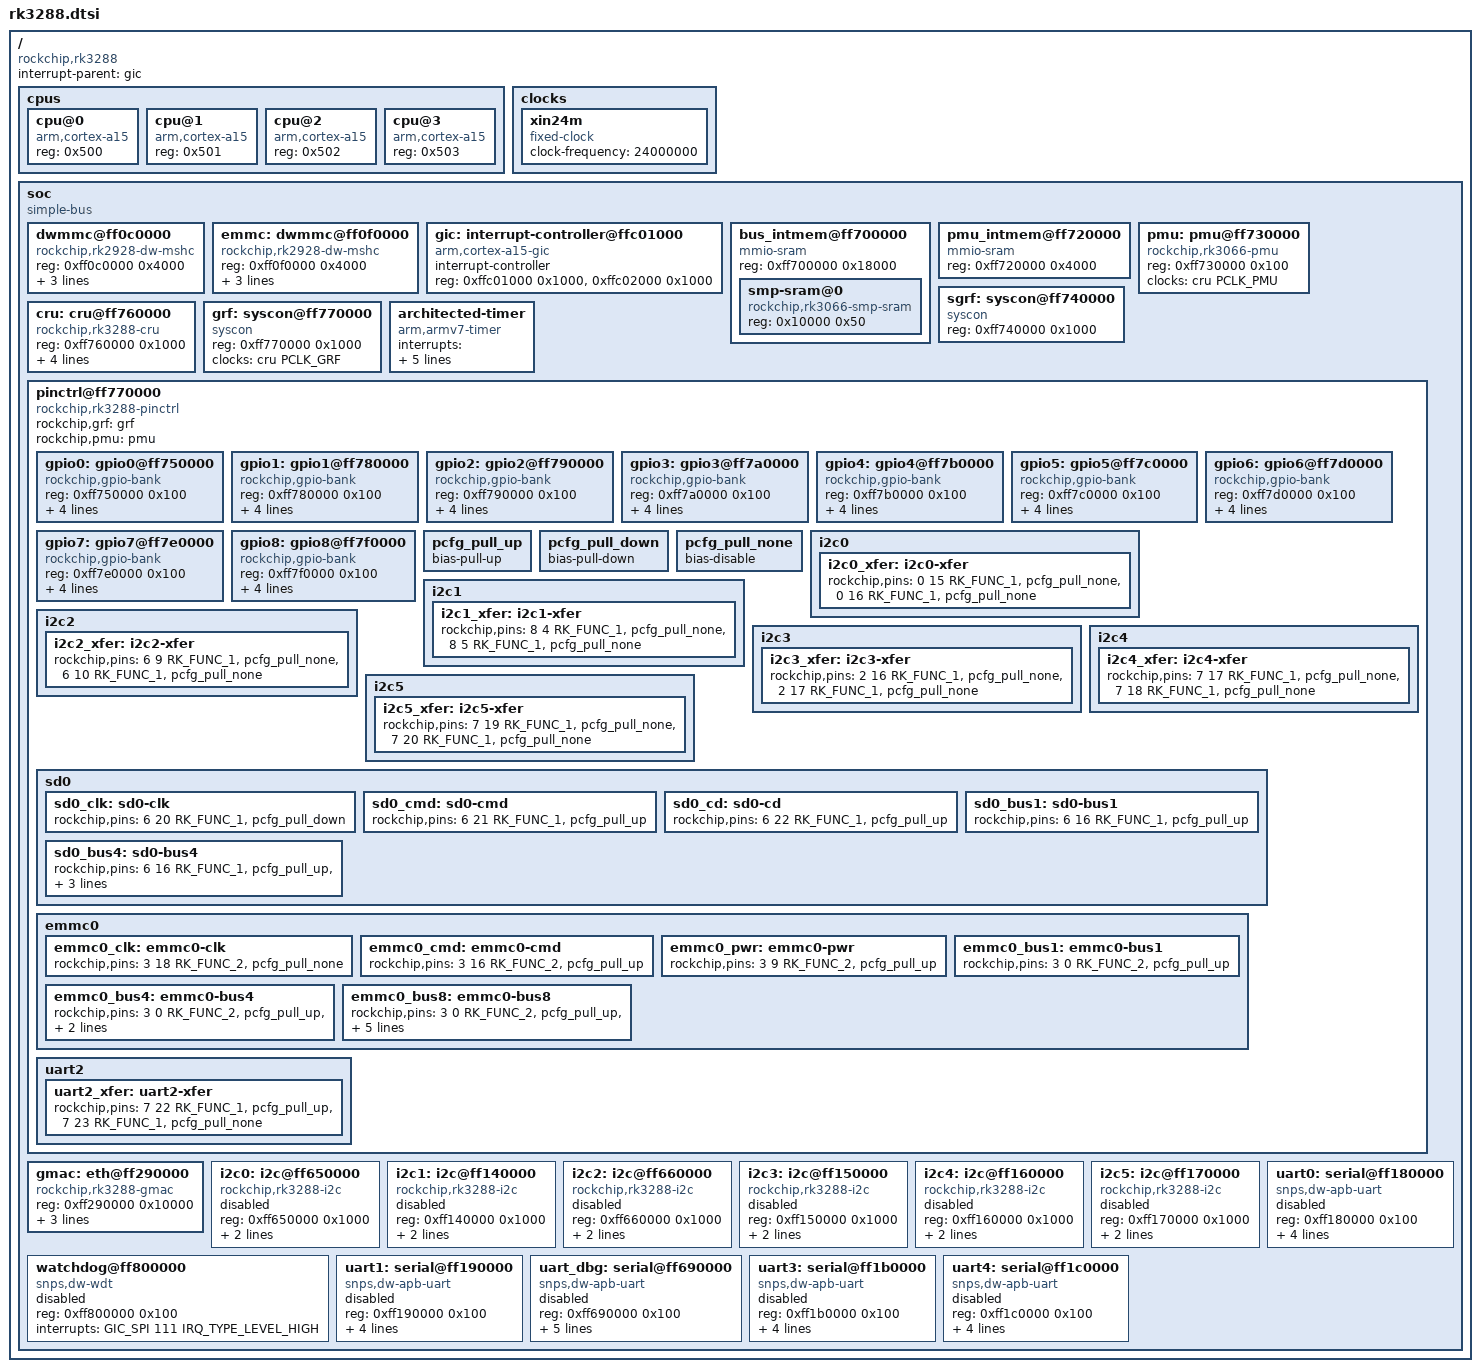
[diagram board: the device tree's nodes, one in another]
/*
 * This program is free software; you can redistribute it and/or modify
 * it under the terms of the GNU General Public License as published by
 * the Free Software Foundation; either version 2 of the License, or
 * (at your option) any later version.
 *
 * This program is distributed in the hope that it will be useful,
 * but WITHOUT ANY WARRANTY; without even the implied warranty of
 * MERCHANTABILITY or FITNESS FOR A PARTICULAR PURPOSE.  See the
 * GNU General Public License for more details.
 */

#include <dt-bindings/gpio/gpio.h>
#include <dt-bindings/interrupt-controller/irq.h>
#include <dt-bindings/interrupt-controller/arm-gic.h>
#include <dt-bindings/pinctrl/rockchip.h>
#include <dt-bindings/clock/rk3288-cru.h>
#include "skeleton.dtsi"

/ {
	compatible = "rockchip,rk3288";

	interrupt-parent = <&gic>;

	cpus {
		#address-cells = <1>;
		#size-cells = <0>;
//		enable-method = "rockchip,rk3288-smp";

		cpu@0 {
			device_type = "cpu";
			compatible = "arm,cortex-a15";
			reg = <0x500>;
		};
		cpu@1 {
			device_type = "cpu";
			compatible = "arm,cortex-a15";
			reg = <0x501>;
		};
		cpu@2 {
			device_type = "cpu";
			compatible = "arm,cortex-a15";
			reg = <0x502>;
		};
		cpu@3 {
			device_type = "cpu";
			compatible = "arm,cortex-a15";
			reg = <0x503>;
		};
	};

	clocks {
		#address-cells = <1>;
		#size-cells = <1>;
		ranges;

		xin24m: xin24m {
			compatible = "fixed-clock";
			clock-frequency = <24000000>;
			#clock-cells = <0>;
		};
	};

	soc {
		#address-cells = <1>;
		#size-cells = <1>;
		compatible = "simple-bus";
		ranges;

		dwmmc@ff0c0000 {
			compatible = "rockchip,rk2928-dw-mshc";
			reg = <0xff0c0000 0x4000>;
			interrupts = <GIC_SPI 32 IRQ_TYPE_LEVEL_HIGH>;
			#address-cells = <1>;
			#size-cells = <0>;

			clocks = <&cru HCLK_SDMMC>, <&cru SCLK_SDMMC>;
			clock-names = "biu", "ciu";

			//FIXME: necessary?
			fifo-depth = <0x100>;
		};

		emmc: dwmmc@ff0f0000 {
			compatible = "rockchip,rk2928-dw-mshc";
			reg = <0xff0f0000 0x4000>;
			interrupts = <GIC_SPI 35 IRQ_TYPE_LEVEL_HIGH>;
			#address-cells = <1>;
			#size-cells = <0>;

			clocks = <&cru HCLK_EMMC>, <&cru SCLK_EMMC>;
			clock-names = "biu", "ciu";

			fifo-depth = <0x100>;
		};

		gic: interrupt-controller@ffc01000 {
			compatible = "arm,cortex-a15-gic";
			interrupt-controller;
			#interrupt-cells = <3>;
			#address-cells = <0>;
			reg = <0xffc01000 0x1000>,
			      <0xffc02000 0x1000>;
		};

		bus_intmem@ff700000 {
			compatible = "mmio-sram";
			reg = <0xff700000 0x18000>;
			#address-cells = <1>;
			#size-cells = <1>;
			ranges = <0 0xff700000 0x18000>;

			smp-sram@0 {
				compatible = "rockchip,rk3066-smp-sram";
				reg = <0x10000 0x50>;
			};
		};

		pmu_intmem@ff720000 {
			compatible = "mmio-sram";
			reg = <0xff720000 0x4000>;
		};

		pmu: pmu@ff730000 {
			compatible = "rockchip,rk3066-pmu", "syscon";
			reg = <0xff730000 0x100>;
			clocks = <&cru PCLK_PMU>;
		};

		sgrf: syscon@ff740000 {
			compatible = "syscon";
			reg = <0xff740000 0x1000>;
		};

		cru: cru@ff760000 {
			compatible = "rockchip,rk3288-cru";
			reg = <0xff760000 0x1000>;

			#clock-cells = <1>;
			#reset-cells = <1>;

			#rockchip,armclk-cells = <3>;
			rockchip,armclk-divider-table = 
/*							<2208000 2 4>,
							<2184000 2 4>,
							<2160000 2 4>,
							<2136000 2 4>,
							<2112000 2 4>,
							<2088000 2 4>,
							<2064000 2 4>,
							<2040000 2 4>,
							<2016000 2 4>,
							<1992000 2 4>,
							<1968000 2 4>,
							<1944000 2 4>,
							<1920000 2 4>,
							<1896000 2 4>,
							<1872000 2 4>,
							<1848000 2 4>,
							<1824000 2 4>,
							<1800000 2 4>,
							<1776000 2 4>,
							<1752000 2 4>,
							<1728000 2 4>,
							<1704000 2 4>,
							<1680000 2 3>,
							<1656000 2 3>,
							<1632000 2 3>, */
							<1608000 2 3>,
/*							<1560000 2 3>,
							<1512000 2 3>,
							<1488000 2 3>,
							<1464000 2 3>,
							<1440000 2 3>, */
							<1416000 2 3>,
/*							<1392000 2 3>,
							<1368000 2 3>,
							<1344000 2 3>,
							<1320000 2 3>,
							<1296000 2 3>,
							<1272000 2 3>,
							<1248000 2 3>,
							<1224000 2 3>, */
							<1200000 2 3>,
/*							<1176000 2 3>,
							<1128000 2 3>,
							<1104000 2 3>, */
							<1008000 2 3>,
/*							< 912000 2 3>,
							< 888000 2 3>, */
							< 816000 2 3>,
/*							< 792000 2 3>,
							< 696000 2 3>, */
							< 600000 1 3>,
							< 504000 1 3>,
//							< 408000 1 1>,
							< 312000 0 1>;
/*							< 252000 0 1>,
							< 216000 0 1>,
							< 126000 0 0>,
							<  48000 0 0> */
		};

		grf: syscon@ff770000 {
			compatible = "syscon";
			reg = <0xff770000 0x1000>;
			clocks = <&cru PCLK_GRF>;
		};

		architected-timer {
			compatible = "arm,armv7-timer";
			interrupts = <GIC_PPI 13 (GIC_CPU_MASK_SIMPLE(4) | IRQ_TYPE_LEVEL_HIGH)>,
				     <GIC_PPI 14 (GIC_CPU_MASK_SIMPLE(4) | IRQ_TYPE_LEVEL_HIGH)>,
				     <GIC_PPI 11 (GIC_CPU_MASK_SIMPLE(4) | IRQ_TYPE_LEVEL_HIGH)>,
				     <GIC_PPI 10 (GIC_CPU_MASK_SIMPLE(4) | IRQ_TYPE_LEVEL_HIGH)>;
			clock-frequency = <24000000>;
		};

		pinctrl@ff770000 {
			compatible = "rockchip,rk3288-pinctrl";
			rockchip,grf = <&grf>;
			rockchip,pmu = <&pmu>;

			#address-cells = <1>;
			#size-cells = <1>;
			ranges;

			gpio0: gpio0@ff750000 {
				compatible = "rockchip,gpio-bank";
				reg =	<0xff750000 0x100>;
				interrupts = <GIC_SPI 81 IRQ_TYPE_LEVEL_HIGH>;
				clocks = <&cru PCLK_GPIO0>;

				gpio-controller;
				#gpio-cells = <2>;

				interrupt-controller;
				#interrupt-cells = <2>;
			};

			gpio1: gpio1@ff780000 {
				compatible = "rockchip,gpio-bank";
				reg = <0xff780000 0x100>;
				interrupts = <GIC_SPI 82 IRQ_TYPE_LEVEL_HIGH>;
				clocks = <&cru PCLK_GPIO1>;

				gpio-controller;
				#gpio-cells = <2>;

				interrupt-controller;
				#interrupt-cells = <2>;
			};

			gpio2: gpio2@ff790000 {
				compatible = "rockchip,gpio-bank";
				reg = <0xff790000 0x100>;
				interrupts = <GIC_SPI 83 IRQ_TYPE_LEVEL_HIGH>;
				clocks = <&cru PCLK_GPIO2>;

				gpio-controller;
				#gpio-cells = <2>;

				interrupt-controller;
				#interrupt-cells = <2>;
			};

			gpio3: gpio3@ff7a0000 {
				compatible = "rockchip,gpio-bank";
				reg = <0xff7a0000 0x100>;
				interrupts = <GIC_SPI 84 IRQ_TYPE_LEVEL_HIGH>;
				clocks = <&cru PCLK_GPIO3>;

				gpio-controller;
				#gpio-cells = <2>;

				interrupt-controller;
				#interrupt-cells = <2>;
			};

			gpio4: gpio4@ff7b0000 {
				compatible = "rockchip,gpio-bank";
				reg = <0xff7b0000 0x100>;
				interrupts = <GIC_SPI 85 IRQ_TYPE_LEVEL_HIGH>;
				clocks = <&cru PCLK_GPIO4>;

				gpio-controller;
				#gpio-cells = <2>;

				interrupt-controller;
				#interrupt-cells = <2>;
			};

			gpio5: gpio5@ff7c0000 {
				compatible = "rockchip,gpio-bank";
				reg = <0xff7c0000 0x100>;
				interrupts = <GIC_SPI 86 IRQ_TYPE_LEVEL_HIGH>;
				clocks = <&cru PCLK_GPIO5>;

				gpio-controller;
				#gpio-cells = <2>;

				interrupt-controller;
				#interrupt-cells = <2>;
			};

			gpio6: gpio6@ff7d0000 {
				compatible = "rockchip,gpio-bank";
				reg = <0xff7d0000 0x100>;
				interrupts = <GIC_SPI 87 IRQ_TYPE_LEVEL_HIGH>;
				clocks = <&cru PCLK_GPIO6>;

				gpio-controller;
				#gpio-cells = <2>;

				interrupt-controller;
				#interrupt-cells = <2>;
			};

			gpio7: gpio7@ff7e0000 {
				compatible = "rockchip,gpio-bank";
				reg = <0xff7e0000 0x100>;
				interrupts = <GIC_SPI 88 IRQ_TYPE_LEVEL_HIGH>;
				clocks = <&cru PCLK_GPIO7>;

				gpio-controller;
				#gpio-cells = <2>;

				interrupt-controller;
				#interrupt-cells = <2>;
			};

			gpio8: gpio8@ff7f0000 {
				compatible = "rockchip,gpio-bank";
				reg = <0xff7f0000 0x100>;
				interrupts = <GIC_SPI 89 IRQ_TYPE_LEVEL_HIGH>;
				clocks = <&cru PCLK_GPIO8>;

				gpio-controller;
				#gpio-cells = <2>;

				interrupt-controller;
				#interrupt-cells = <2>;
			};

			/* FIXME what is gpio15 */

			pcfg_pull_up: pcfg_pull_up {
				bias-pull-up;
			};

			pcfg_pull_down: pcfg_pull_down {
				bias-pull-down;
			};

			pcfg_pull_none: pcfg_pull_none {
				bias-disable;
			};

			i2c0 {
				i2c0_xfer: i2c0-xfer {
					rockchip,pins = <0 15 RK_FUNC_1 &pcfg_pull_none>,
							<0 16 RK_FUNC_1 &pcfg_pull_none>;
				};
			};

			i2c1 {
				i2c1_xfer: i2c1-xfer {
					rockchip,pins = <8 4 RK_FUNC_1 &pcfg_pull_none>,
							<8 5 RK_FUNC_1 &pcfg_pull_none>;
				};
			};

			i2c2 {
				i2c2_xfer: i2c2-xfer {
					rockchip,pins = <6 9 RK_FUNC_1 &pcfg_pull_none>,
							<6 10 RK_FUNC_1 &pcfg_pull_none>;
				};
			};

			i2c3 {
				i2c3_xfer: i2c3-xfer {
					rockchip,pins = <2 16 RK_FUNC_1 &pcfg_pull_none>,
							<2 17 RK_FUNC_1 &pcfg_pull_none>;
				};
			};

			i2c4 {
				i2c4_xfer: i2c4-xfer {
					rockchip,pins = <7 17 RK_FUNC_1 &pcfg_pull_none>,
							<7 18 RK_FUNC_1 &pcfg_pull_none>;
				};
			};

			i2c5 {
				i2c5_xfer: i2c5-xfer {
					rockchip,pins = <7 19 RK_FUNC_1 &pcfg_pull_none>,
							<7 20 RK_FUNC_1 &pcfg_pull_none>;
				};
			};

			sd0 {
				sd0_clk: sd0-clk {
					rockchip,pins = <6 20 RK_FUNC_1 &pcfg_pull_down>;
				};

				sd0_cmd: sd0-cmd {
					rockchip,pins = <6 21 RK_FUNC_1 &pcfg_pull_up>;
				};

				sd0_cd: sd0-cd{
					rockchip,pins = <6 22 RK_FUNC_1 &pcfg_pull_up>;
				};


				sd0_bus1: sd0-bus1 {
					rockchip,pins = <6 16 RK_FUNC_1 &pcfg_pull_up>;
				};

				sd0_bus4: sd0-bus4 {
					rockchip,pins = <6 16 RK_FUNC_1 &pcfg_pull_up>,
							<6 17 RK_FUNC_1 &pcfg_pull_up>,
							<6 18 RK_FUNC_1 &pcfg_pull_up>,
							<6 19 RK_FUNC_1 &pcfg_pull_up>;
				};
			};

			emmc0 {
				emmc0_clk: emmc0-clk {
					rockchip,pins = <3 18 RK_FUNC_2 &pcfg_pull_none>;
				};

				emmc0_cmd: emmc0-cmd {
					rockchip,pins = <3 16 RK_FUNC_2 &pcfg_pull_up>;
				};

				emmc0_pwr: emmc0-pwr {
					rockchip,pins = <3 9 RK_FUNC_2 &pcfg_pull_up>;
				};


				emmc0_bus1: emmc0-bus1 {
					rockchip,pins = <3 0 RK_FUNC_2 &pcfg_pull_up>;
				};

				emmc0_bus4: emmc0-bus4 {
					rockchip,pins = <3 0 RK_FUNC_2 &pcfg_pull_up>,
							<3 1 RK_FUNC_2 &pcfg_pull_up>,
							<3 2 RK_FUNC_2 &pcfg_pull_up>,
							<3 3 RK_FUNC_2 &pcfg_pull_up>;
				};

				emmc0_bus8: emmc0-bus8 {
					rockchip,pins = <3 0 RK_FUNC_2 &pcfg_pull_up>,
							<3 1 RK_FUNC_2 &pcfg_pull_up>,
							<3 2 RK_FUNC_2 &pcfg_pull_up>,
							<3 3 RK_FUNC_2 &pcfg_pull_up>,
							<3 4 RK_FUNC_2 &pcfg_pull_up>,
							<3 5 RK_FUNC_2 &pcfg_pull_up>,
							<3 6 RK_FUNC_2 &pcfg_pull_up>,
							<3 7 RK_FUNC_2 &pcfg_pull_up>;
				};
			};

			uart2 {
				uart2_xfer: uart2-xfer {
					rockchip,pins = <7 22 RK_FUNC_1 &pcfg_pull_up>,
							<7 23 RK_FUNC_1 &pcfg_pull_none>;
				};
				/* no rts / cts for uart2 */
			};

		};

		gmac: eth@ff290000 {
			compatible = "rockchip,rk3288-gmac";
			reg = <0xff290000 0x10000>;
			interrupts = <GIC_SPI 27 IRQ_TYPE_LEVEL_HIGH>;

			rockchip,grf = <&grf>;

			//phy-mode = "rmii";
			phy-mode = "rgmii";
//			clocks = <&cru PCLK_GMAC>, <&gmac_tx>;
			clock-names = "stmmaceth", "rockchip_gmac_aclk", "rockchip_gmac_tx", "rockchip_gmac_rx";
//			clocks = <>;
//			pinctrl-names = "default";
//			pinctrl-0 = <&mac_clk &mac_txpins &mac_rxpins &mac_mdpins>;
		};

		i2c0: i2c@ff650000 {
			compatible = "rockchip,rk3288-i2c";
			reg = <0xff650000 0x1000>;
			interrupts = <GIC_SPI 60 IRQ_TYPE_LEVEL_HIGH>;
			#address-cells = <1>;
			#size-cells = <0>;

			clock-names = "i2c";
			clocks = <&cru PCLK_I2C0>;

			status = "disabled";
		};

		i2c1: i2c@ff140000 {
			compatible = "rockchip,rk3288-i2c";
			reg = <0xff140000 0x1000>;
			interrupts = <GIC_SPI 62 IRQ_TYPE_LEVEL_HIGH>;
			#address-cells = <1>;
			#size-cells = <0>;

			clock-names = "i2c";
			clocks = <&cru PCLK_I2C1>;

			status = "disabled";
		};

		i2c2: i2c@ff660000 {
			compatible = "rockchip,rk3288-i2c";
			reg = <0xff660000 0x1000>;
			interrupts = <GIC_SPI 61 IRQ_TYPE_LEVEL_HIGH>;
			#address-cells = <1>;
			#size-cells = <0>;

			clock-names = "i2c";
			clocks = <&cru PCLK_I2C2>;

			status = "disabled";
		};

		i2c3: i2c@ff150000 {
			compatible = "rockchip,rk3288-i2c";
			reg = <0xff150000 0x1000>;
			interrupts = <GIC_SPI 63 IRQ_TYPE_LEVEL_HIGH>;
			#address-cells = <1>;
			#size-cells = <0>;

			clock-names = "i2c";
			clocks = <&cru PCLK_I2C3>;

			status = "disabled";
		};

		i2c4: i2c@ff160000 {
			compatible = "rockchip,rk3288-i2c";
			reg = <0xff160000 0x1000>;
			interrupts = <GIC_SPI 64 IRQ_TYPE_LEVEL_HIGH>;
			#address-cells = <1>;
			#size-cells = <0>;

			clock-names = "i2c";
			clocks = <&cru PCLK_I2C4>;

			status = "disabled";
		};

		i2c5: i2c@ff170000 {
			compatible = "rockchip,rk3288-i2c";
			reg = <0xff170000 0x1000>;
			interrupts = <GIC_SPI 65 IRQ_TYPE_LEVEL_HIGH>;
			#address-cells = <1>;
			#size-cells = <0>;

			clock-names = "i2c";
			clocks = <&cru PCLK_I2C5>;

			status = "disabled";
		};

		watchdog@ff800000 {
			compatible = "snps,dw-wdt";
			reg = <0xff800000 0x100>;
			interrupts = <GIC_SPI 111 IRQ_TYPE_LEVEL_HIGH>;
//			clocks = <&per_base_clk>;
			status = "disable";
		};

		/* uart_bt */
		uart0: serial@ff180000 {
			compatible = "snps,dw-apb-uart";
			reg = <0xff180000 0x100>;
			interrupts = <GIC_SPI 55 IRQ_TYPE_LEVEL_HIGH>;
			reg-shift = <2>;
			reg-io-width = <4>;
			clocks = <&cru SCLK_UART0>, <&cru PCLK_UART0>;
			clock-names = "baudclk", "apb_pclk";
			status = "disabled";
		};

		/* uart_bb */
		uart1: serial@ff190000 {
			compatible = "snps,dw-apb-uart";
			reg = <0xff190000 0x100>;
			interrupts = <GIC_SPI 56 IRQ_TYPE_LEVEL_HIGH>;
			reg-shift = <2>;
			reg-io-width = <4>;
			clocks = <&cru SCLK_UART1>, <&cru PCLK_UART1>;
			clock-names = "baudclk", "apb_pclk";
			status = "disabled";
		};

		/* uart_dbg */
		uart_dbg: serial@ff690000 {
			compatible = "snps,dw-apb-uart";
			reg = <0xff690000 0x100>;
			interrupts = <GIC_SPI 57 IRQ_TYPE_LEVEL_HIGH>;
			reg-shift = <2>;
			reg-io-width = <4>;
			clocks = <&cru SCLK_UART2>, <&cru PCLK_UART2>;
			clock-names = "baudclk", "apb_pclk";
			status = "disabled";
			pinctrl-names = "default";
			pinctrl-0 = <&uart2_xfer>;
		};

		/* uart_gps */
		uart3: serial@ff1b0000 {
			compatible = "snps,dw-apb-uart";
			reg = <0xff1b0000 0x100>;
			interrupts = <GIC_SPI 58 IRQ_TYPE_LEVEL_HIGH>;
			reg-shift = <2>;
			reg-io-width = <4>;
			clocks = <&cru SCLK_UART3>, <&cru PCLK_UART3>;
			clock-names = "baudclk", "apb_pclk";
			status = "disabled";
		};

		/* uart_exp */
		uart4: serial@ff1c0000 {
			compatible = "snps,dw-apb-uart";
			reg = <0xff1c0000 0x100>;
			interrupts = <GIC_SPI 59 IRQ_TYPE_LEVEL_HIGH>;
			reg-shift = <2>;
			reg-io-width = <4>;
			clocks = <&cru SCLK_UART4>, <&cru PCLK_UART4>;
			clock-names = "baudclk", "apb_pclk";
			status = "disabled";
		};
	};
};
